// Description: LIN Description file created using VDE

// Created: 11/05/2021 18:27:28

// Author: VDE

LIN_description_file;
LIN_protocol_version = "2.1";
LIN_language_version = "2.1";
LIN_speed = 19.2 kbps;

Nodes {
  Master: DDCU, 5 ms, 0.1 ms ;
  Slaves: DFGLS, DRGLS ;
}

Signals {
  DDCU_BDCS1_Backlight_brightness_fb: 4, 3, DDCU, DFGLS, DRGLS;//背光灯亮度调节反馈
  DDCU_ControlWindowLockSwInd: 1, 0, DDCU, DFGLS;//窗锁状态指示灯
  DDCU_BDCS1_BacklightStatus: 1, 0, DDCU, DFGLS, DRGLS;//整车背光灯状态信号 白天、夜晚模式
  DFGLS_ResponseError: 1, 0, DFGLS, DDCU;//通信错误状态反馈信号
  DFGLS_FLWindowControl: 3, 0, DFGLS, DDCU;//左前车窗控制开关
  DFGLS_FRWindowControl: 3, 0, DFGLS, DDCU;//右前车窗控制开关
  DFGLS_ControlWindowLockSw: 1, 0, DFGLS, DDCU;//玻璃锁止控制开关
  DFGLS_ErrorSts: 1, 0, DFGLS, DDCU;//DFGLS故障状态
  DFGLS_RLWindowControl: 3, 0, DFGLS, DDCU;//左后车窗控制开关
  DFGLS_RRWindowControl: 3, 0, DFGLS, DDCU;//右后车窗控制开关
  DFGLS_ButtonSoundRequest: 1, 0, DFGLS, DDCU;//按键声音提示
  DFGLS_Voltage_errorCode: 1, 0, DFGLS, DDCU;//诊断信号
  DFGLS_Capsense_errorCode: 1, 0, DFGLS, DDCU;//诊断信号
  DFGLS_Motor_errorCode: 1, 0, DFGLS, DDCU;//诊断信号
  DRGLS_ResponseError: 1, 0, DRGLS, DDCU;//通信错误状态反馈信号
  DRGLS_FRWindowControl: 3, 0, DRGLS, DDCU;//左后车窗控制开关
  DRGLS_CustomSignal: 1, 0, DRGLS, DDCU;//自定义信号
  DRGLS_ButtonSoundRequest: 1, 0, DRGLS, DDCU;//按键声音提示
  DRGLS_ErrorSts: 1, 0, DRGLS, DDCU;//DRGLS故障状态
  DRGLS_Voltage_errorCode: 1, 0, DRGLS, DDCU;//诊断信号
  DRGLS_Capsense_errorCode: 1, 0, DRGLS, DDCU;//诊断信号
  DRGLS_Motor_errorCode: 1, 0, DRGLS, DDCU;//诊断信号
}

Frames {
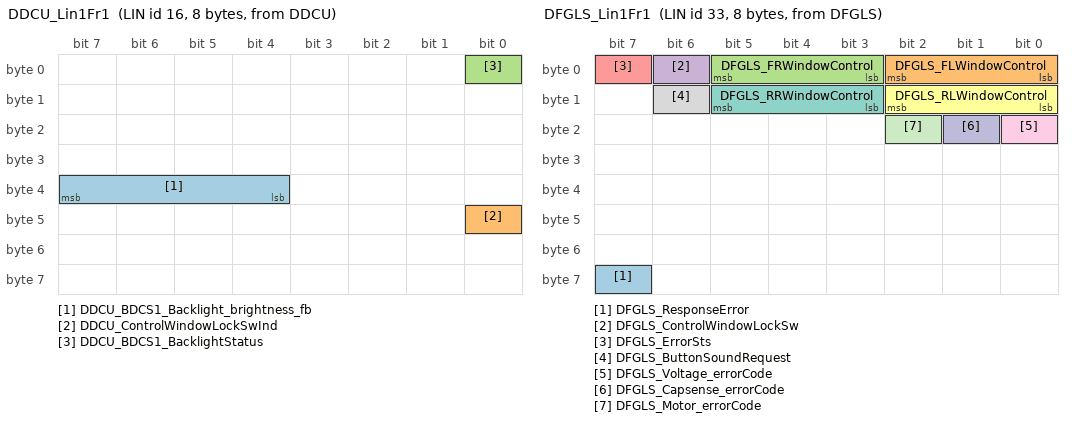
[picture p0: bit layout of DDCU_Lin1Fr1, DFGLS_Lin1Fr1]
  DDCU_Lin1Fr1: 16, DDCU, 8 {
    DDCU_BDCS1_Backlight_brightness_fb, 36 ;
    DDCU_ControlWindowLockSwInd, 40 ;
    DDCU_BDCS1_BacklightStatus, 0 ;
  }
  DFGLS_Lin1Fr1: 33, DFGLS, 8 {
    DFGLS_ResponseError, 63 ;
    DFGLS_FLWindowControl, 0 ;
    DFGLS_FRWindowControl, 3 ;
    DFGLS_ControlWindowLockSw, 6 ;
    DFGLS_ErrorSts, 7 ;
    DFGLS_RLWindowControl, 8 ;
    DFGLS_RRWindowControl, 11 ;
    DFGLS_ButtonSoundRequest, 14 ;
    DFGLS_Voltage_errorCode, 16 ;
    DFGLS_Capsense_errorCode, 17 ;
    DFGLS_Motor_errorCode, 18 ;
  }
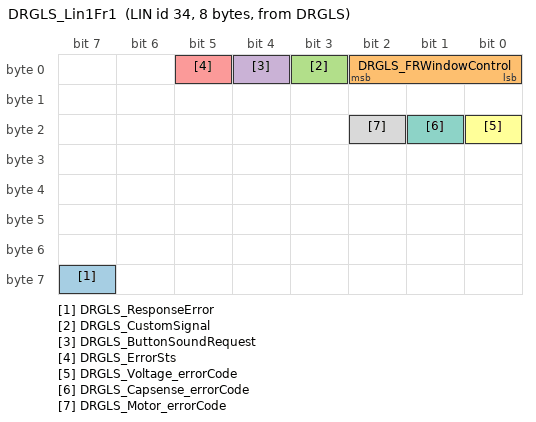
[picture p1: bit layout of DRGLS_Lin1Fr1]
  DRGLS_Lin1Fr1: 34, DRGLS, 8 {
    DRGLS_ResponseError, 63 ;
    DRGLS_FRWindowControl, 0 ;
    DRGLS_CustomSignal, 3 ;
    DRGLS_ButtonSoundRequest, 4 ;
    DRGLS_ErrorSts, 5 ;
    DRGLS_Voltage_errorCode, 16 ;
    DRGLS_Capsense_errorCode, 17 ;
    DRGLS_Motor_errorCode, 18 ;
  }
}

Node_attributes {
  DFGLS{
    LIN_protocol = "2.1" ;
    configured_NAD = 80 ;
    initial_NAD = 80 ;
    product_id = 0x0, 0x0, 0 ;
    response_error = DFGLS_ResponseError ;
    configurable_frames {
      DDCU_Lin1Fr1 ;
      DFGLS_Lin1Fr1 ;
    }
  }
  DRGLS{
    LIN_protocol = "2.1" ;
    configured_NAD = 81 ;
    initial_NAD = 81 ;
    product_id = 0x0, 0x0, 0 ;
    response_error = DRGLS_ResponseError ;
    configurable_frames {
      DDCU_Lin1Fr1 ;
      DRGLS_Lin1Fr1 ;
    }
  }
}

Schedule_tables {
 Dynamic {
    DDCU_Lin1Fr1 delay 10 ms ;
    DFGLS_Lin1Fr1 delay 20 ms ;
    DRGLS_Lin1Fr1 delay 20 ms ;
  }
}

Signal_encoding_types {
  Enc_DDCU_Lin1Fr1_DDCU_BDCS1_Backlight_brightness_fb {
    physical_value, 0, 15, 1, 0, "NoUnit" ;
    logical_value, 1, "Level 1" ;
    logical_value, 2, "Level 2" ;
    logical_value, 3, "Level 3" ;
    logical_value, 4, "Level 4" ;
    logical_value, 5, "Level 5" ;
    logical_value, 6, "Level 6" ;
    logical_value, 7, "Level 7" ;
    logical_value, 8, "Level 8" ;
    logical_value, 9, "Level 9" ;
    logical_value, 10, "Level 10" ;
  }
  Enc_DDCU_Lin1Fr1_DDCU_ControlWindowLockSwInd {
    physical_value, 0, 1, 1, 0, "NoUnit" ;
    logical_value, 0, "Inactive" ;
    logical_value, 1, "Active" ;
  }
  Enc_DDCU_Lin1Fr1_DDCU_BDCS1_BacklightStatus {
    physical_value, 0, 1, 1, 0, "NoUnit" ;
    logical_value, 0, "Inactive" ;
    logical_value, 1, "Active" ;
  }
  Enc_DFGLS_Lin1Fr1_DFGLS_ResponseError {
    physical_value, 0, 1, 1, 0, "NoUnit" ;
    logical_value, 0, "normal" ;
    logical_value, 1, "fault" ;
  }
  Enc_DFGLS_Lin1Fr1_DFGLS_FLWindowControl {
    physical_value, 0, 7, 1, 0, "NoUnit" ;
    logical_value, 0, "No request" ;
    logical_value, 1, "Manual Up" ;
    logical_value, 2, "Manual Down" ;
    logical_value, 3, "Auto Up " ;
    logical_value, 4, "Auto Down" ;
  }
  Enc_DFGLS_Lin1Fr1_DFGLS_FRWindowControl {
    physical_value, 0, 7, 1, 0, "NoUnit" ;
    logical_value, 0, "No request" ;
    logical_value, 1, "Manual Up" ;
    logical_value, 2, "Manual Down" ;
    logical_value, 3, "Auto Up " ;
    logical_value, 4, "Auto Down" ;
  }
  Enc_DFGLS_Lin1Fr1_DFGLS_ControlWindowLockSw {
    physical_value, 0, 1, 1, 0, "NoUnit" ;
    logical_value, 0, "Inactive" ;
    logical_value, 1, "Active" ;
  }
  Enc_DFGLS_Lin1Fr1_DFGLS_ErrorSts {
    physical_value, 0, 1, 1, 0, "NoUnit" ;
    logical_value, 0, "No error" ;
    logical_value, 1, "Error" ;
  }
  Enc_DFGLS_Lin1Fr1_DFGLS_RLWindowControl {
    physical_value, 0, 7, 1, 0, "NoUnit" ;
    logical_value, 0, "No request" ;
    logical_value, 1, "Manual Up" ;
    logical_value, 2, "Manual Down" ;
    logical_value, 3, "Auto Up " ;
    logical_value, 4, "Auto Down" ;
  }
  Enc_DFGLS_Lin1Fr1_DFGLS_RRWindowControl {
    physical_value, 0, 7, 1, 0, "NoUnit" ;
    logical_value, 0, "No request" ;
    logical_value, 1, "Manual Up" ;
    logical_value, 2, "Manual Down" ;
    logical_value, 3, "Auto Up " ;
    logical_value, 4, "Auto Down" ;
  }
  Enc_DFGLS_Lin1Fr1_DFGLS_ButtonSoundRequest {
    physical_value, 0, 1, 1, 0, "NoUnit" ;
    logical_value, 0, "NO Press" ;
    logical_value, 1, "Press" ;
  }
  Enc_DFGLS_Lin1Fr1_DFGLS_Voltage_errorCode {
    physical_value, 0, 1, 1, 0, "NoUnit" ;
    logical_value, 0, "No error" ;
    logical_value, 1, "Error" ;
  }
  Enc_DFGLS_Lin1Fr1_DFGLS_Capsense_errorCode {
    physical_value, 0, 1, 1, 0, "NoUnit" ;
    logical_value, 0, "No error" ;
    logical_value, 1, "Error" ;
  }
  Enc_DFGLS_Lin1Fr1_DFGLS_Motor_errorCode {
    physical_value, 0, 1, 1, 0, "NoUnit" ;
    logical_value, 0, "No error" ;
    logical_value, 1, "Error" ;
  }
  Enc_DRGLS_Lin1Fr1_DRGLS_ResponseError {
    physical_value, 0, 1, 1, 0, "NoUnit" ;
    logical_value, 0, "normal" ;
    logical_value, 1, "fault" ;
  }
  Enc_DRGLS_Lin1Fr1_DRGLS_FRWindowControl {
    physical_value, 0, 7, 1, 0, "NoUnit" ;
    logical_value, 0, "No request" ;
    logical_value, 1, "Manual Up" ;
    logical_value, 2, "Manual Down" ;
    logical_value, 3, "Auto Up " ;
    logical_value, 4, "Auto Down" ;
  }
  Enc_DRGLS_Lin1Fr1_DRGLS_CustomSignal {
    physical_value, 0, 1, 1, 0, "NoUnit" ;
    logical_value, 0, "Inactive" ;
    logical_value, 1, "Active" ;
  }
  Enc_DRGLS_Lin1Fr1_DRGLS_ButtonSoundRequest {
    physical_value, 0, 1, 1, 0, "NoUnit" ;
    logical_value, 0, "NO Press" ;
    logical_value, 1, "Press" ;
  }
  Enc_DRGLS_Lin1Fr1_DRGLS_ErrorSts {
    physical_value, 0, 1, 1, 0, "NoUnit" ;
    logical_value, 0, "No error" ;
    logical_value, 1, "Error" ;
  }
  Enc_DRGLS_Lin1Fr1_DRGLS_Voltage_errorCode {
    physical_value, 0, 1, 1, 0, "NoUnit" ;
    logical_value, 0, "No error" ;
    logical_value, 1, "Error" ;
  }
  Enc_DRGLS_Lin1Fr1_DRGLS_Capsense_errorCode {
    physical_value, 0, 1, 1, 0, "NoUnit" ;
    logical_value, 0, "No error" ;
    logical_value, 1, "Error" ;
  }
  Enc_DRGLS_Lin1Fr1_DRGLS_Motor_errorCode {
    physical_value, 0, 1, 1, 0, "NoUnit" ;
    logical_value, 0, "No error" ;
    logical_value, 1, "Error" ;
  }
}

Signal_representation {
  Enc_DDCU_Lin1Fr1_DDCU_BDCS1_Backlight_brightness_fb: DDCU_BDCS1_Backlight_brightness_fb ;
  Enc_DDCU_Lin1Fr1_DDCU_ControlWindowLockSwInd: DDCU_ControlWindowLockSwInd ;
  Enc_DDCU_Lin1Fr1_DDCU_BDCS1_BacklightStatus: DDCU_BDCS1_BacklightStatus ;
  Enc_DFGLS_Lin1Fr1_DFGLS_ResponseError: DFGLS_ResponseError ;
  Enc_DFGLS_Lin1Fr1_DFGLS_FLWindowControl: DFGLS_FLWindowControl ;
  Enc_DFGLS_Lin1Fr1_DFGLS_FRWindowControl: DFGLS_FRWindowControl ;
  Enc_DFGLS_Lin1Fr1_DFGLS_ControlWindowLockSw: DFGLS_ControlWindowLockSw ;
  Enc_DFGLS_Lin1Fr1_DFGLS_ErrorSts: DFGLS_ErrorSts ;
  Enc_DFGLS_Lin1Fr1_DFGLS_RLWindowControl: DFGLS_RLWindowControl ;
  Enc_DFGLS_Lin1Fr1_DFGLS_RRWindowControl: DFGLS_RRWindowControl ;
  Enc_DFGLS_Lin1Fr1_DFGLS_ButtonSoundRequest: DFGLS_ButtonSoundRequest ;
  Enc_DFGLS_Lin1Fr1_DFGLS_Voltage_errorCode: DFGLS_Voltage_errorCode ;
  Enc_DFGLS_Lin1Fr1_DFGLS_Capsense_errorCode: DFGLS_Capsense_errorCode ;
  Enc_DFGLS_Lin1Fr1_DFGLS_Motor_errorCode: DFGLS_Motor_errorCode ;
  Enc_DRGLS_Lin1Fr1_DRGLS_ResponseError: DRGLS_ResponseError ;
  Enc_DRGLS_Lin1Fr1_DRGLS_FRWindowControl: DRGLS_FRWindowControl ;
  Enc_DRGLS_Lin1Fr1_DRGLS_CustomSignal: DRGLS_CustomSignal ;
  Enc_DRGLS_Lin1Fr1_DRGLS_ButtonSoundRequest: DRGLS_ButtonSoundRequest ;
  Enc_DRGLS_Lin1Fr1_DRGLS_ErrorSts: DRGLS_ErrorSts ;
  Enc_DRGLS_Lin1Fr1_DRGLS_Voltage_errorCode: DRGLS_Voltage_errorCode ;
  Enc_DRGLS_Lin1Fr1_DRGLS_Capsense_errorCode: DRGLS_Capsense_errorCode ;
  Enc_DRGLS_Lin1Fr1_DRGLS_Motor_errorCode: DRGLS_Motor_errorCode ;
}
